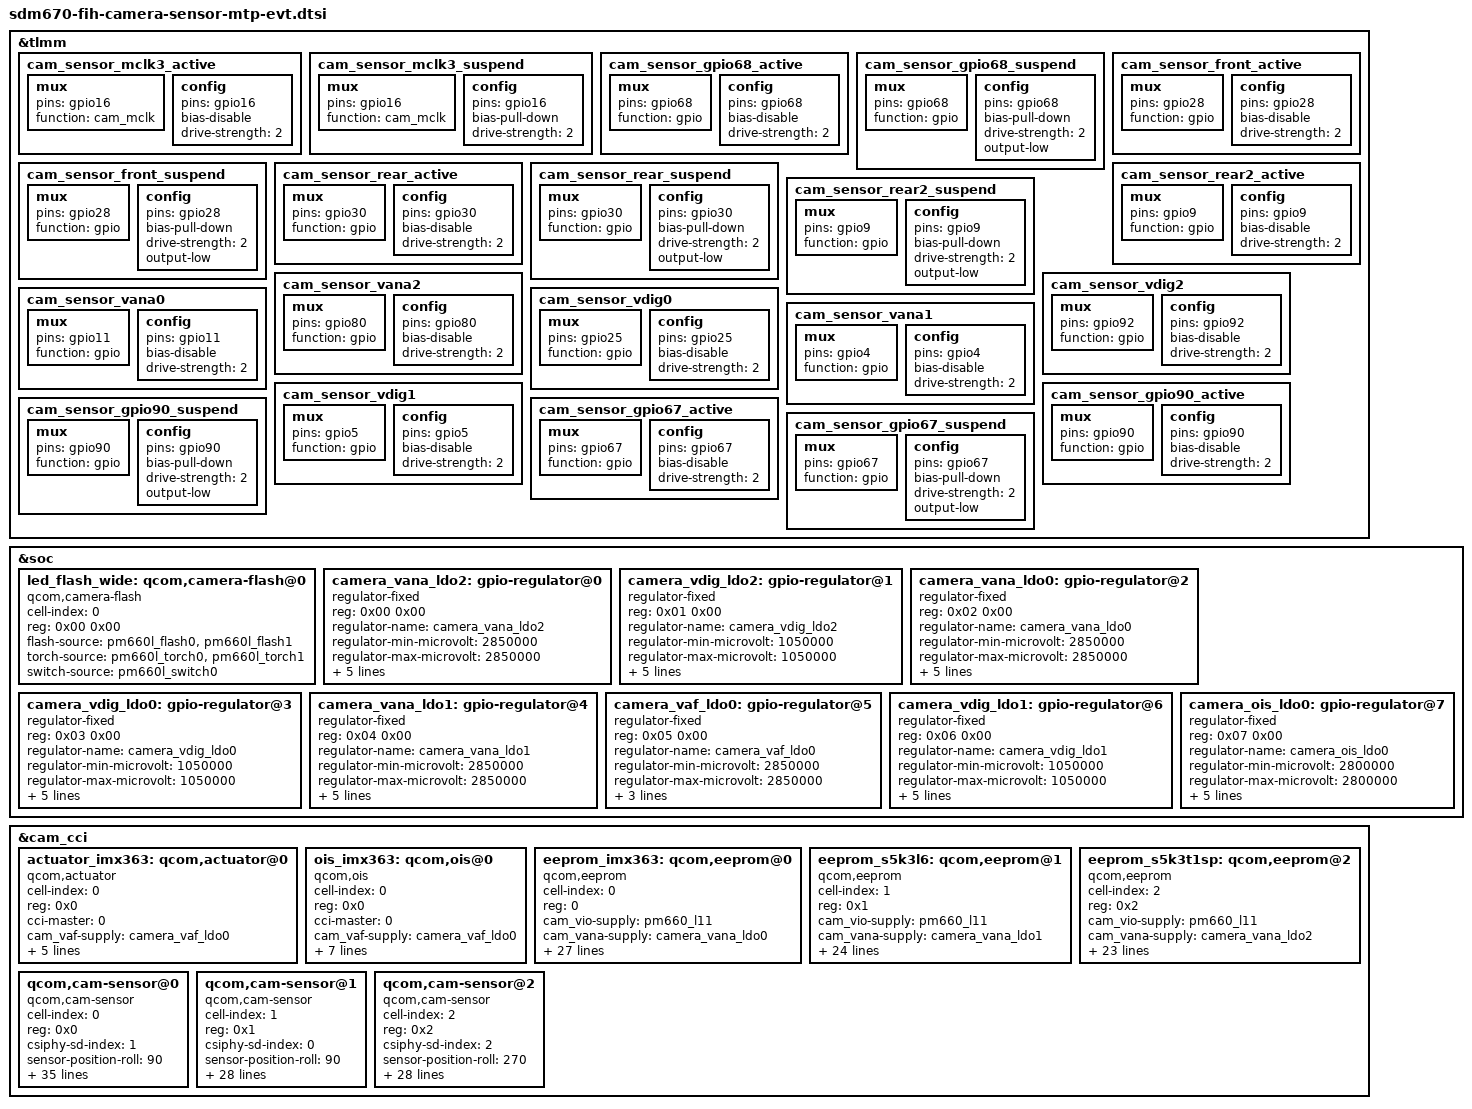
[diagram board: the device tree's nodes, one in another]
/*
 * Base on sdm670-camera-sensor-mtp.dtsi to overwrite setting
 */
 
&tlmm {
	/* Delete pinctrl node*/
	/delete-node/cam_sensor_front_active;
	/delete-node/cam_sensor_front_suspend;
	/delete-node/cam_sensor_rear_active;
	/delete-node/cam_sensor_rear_suspend;
	/delete-node/cam_sensor_rear2_active;
	/delete-node/cam_sensor_rear2_suspend;

	cam_sensor_mclk3_active: cam_sensor_mclk3_active {
		/* MCLK3 */
		mux {
			pins = "gpio16";
			function = "cam_mclk";
		};

		config {
			pins = "gpio16";
			bias-disable; /* No PULL */
			drive-strength = <2>; /* 2 MA */
		};
	};

	cam_sensor_mclk3_suspend: cam_sensor_mclk3_suspend {
		/* MCLK3 */
		mux {
			pins = "gpio16";
			function = "cam_mclk";
		};

		config {
			pins = "gpio16";
			bias-pull-down; /* PULL DOWN */
			drive-strength = <2>; /* 2 MA */
		};
	};

	cam_sensor_gpio68_active: cam_sensor_gpio68_active {
		/* RESET  */
		mux {
			pins = "gpio68";
			function = "gpio";
		};

		config {
			pins = "gpio68";
			bias-disable; /* No PULL */
			drive-strength = <2>; /* 2 MA */
		};
	};

	cam_sensor_gpio68_suspend: cam_sensor_gpio68_suspend {
		/* RESET */
		mux {
			pins = "gpio68";
			function = "gpio";
		};

		config {
			pins = "gpio68";
			bias-pull-down; /* PULL DOWN */
			drive-strength = <2>; /* 2 MA */
			output-low;
		};
	};

	cam_sensor_front_active: cam_sensor_front_active {
		/* RESET  */
		mux {
			pins = "gpio28";
			function = "gpio";
		};

		config {
			pins = "gpio28";
			bias-disable; /* No PULL */
			drive-strength = <2>; /* 2 MA */
		};
	};

	cam_sensor_front_suspend: cam_sensor_front_suspend {
		/* RESET */
		mux {
			pins = "gpio28";
			function = "gpio";
		};

		config {
			pins = "gpio28";
			bias-pull-down; /* PULL DOWN */
			drive-strength = <2>; /* 2 MA */
			output-low;
		};
	};

	cam_sensor_rear_active: cam_sensor_rear_active {
		/* RESET */
		mux {
			pins = "gpio30";
			function = "gpio";
		};

		config {
			pins = "gpio30";
			bias-disable; /* No PULL */
			drive-strength = <2>; /* 2 MA */
		};
	};

	cam_sensor_rear_suspend: cam_sensor_rear_suspend {
		/* RESET */
		mux {
			pins = "gpio30";
			function = "gpio";
		};

		config {
			pins = "gpio30";
			bias-pull-down; /* PULL DOWN */
			drive-strength = <2>; /* 2 MA */
			output-low;
		};
	};

	cam_sensor_rear2_active: cam_sensor_rear2_active {
		/* RESET */
		mux {
			pins = "gpio9";
			function = "gpio";
		};

		config {
			pins = "gpio9";
			bias-disable; /* No PULL */
			drive-strength = <2>; /* 2 MA */
		};
	};

	cam_sensor_rear2_suspend: cam_sensor_rear2_suspend {
		/* RESET */
		mux {
			pins = "gpio9";
			function = "gpio";
		};

		config {
			pins = "gpio9";
			bias-pull-down; /* PULL DOWN */
			drive-strength = <2>; /* 2 MA */
			output-low;
		};
	};
	
	cam_sensor_vana2: cam_sensor_vana2 {
		/*  FRONT AVDD LDO */
		mux {
			pins = "gpio80";
			function = "gpio";
		};

		config {
			pins = "gpio80";
			bias-disable; /* No PULL */
			drive-strength = <2>; /* 2 MA */
		};
	};

	cam_sensor_vdig2: cam_sensor_vdig2 {
		/*  FRONT VDIG LDO */
		mux {
			pins = "gpio92";
			function = "gpio";
		};

		config {
			pins = "gpio92";
			bias-disable; /* No PULL */
			drive-strength = <2>; /* 2 MA */
		};
	};

	cam_sensor_vana0: cam_sensor_vana0 {
		/*  WIDE AVDD LDO */
		mux {
			pins = "gpio11";
			function = "gpio";
		};

		config {
			pins = "gpio11";
			bias-disable; /* No PULL */
			drive-strength = <2>; /* 2 MA */
		};
	};

	cam_sensor_vdig0: cam_sensor_vdig0 {
		/*  WIDE VDIG LDO */
		mux {
			pins = "gpio25";
			function = "gpio";
		};

		config {
			pins = "gpio25";
			bias-disable; /* No PULL */
			drive-strength = <2>; /* 2 MA */
		};
	};

	cam_sensor_vana1: cam_sensor_vana1 {
		/*  TELE AVDD LDO */
		mux {
			pins = "gpio4";
			function = "gpio";
		};

		config {
			pins = "gpio4";
			bias-disable; /* No PULL */
			drive-strength = <2>; /* 2 MA */
		};
	};

	cam_sensor_vdig1: cam_sensor_vdig1 {
		/*  TELE VDIG LDO */
		mux {
			pins = "gpio5";
			function = "gpio";
		};

		config {
			pins = "gpio5";
			bias-disable; /* No PULL */
			drive-strength = <2>; /* 2 MA */
		};
	};

	cam_sensor_gpio90_active: cam_sensor_gpio90_active {
		/* VAF  */
		mux {
			pins = "gpio90";
			function = "gpio";
		};

		config {
			pins = "gpio90";
			bias-disable; /* No PULL */
			drive-strength = <2>; /* 2 MA */
		};
	};

	cam_sensor_gpio90_suspend: cam_sensor_gpio90_suspend {
		/* VAF */
		mux {
			pins = "gpio90";
			function = "gpio";
		};

		config {
			pins = "gpio90";
			bias-pull-down; /* PULL DOWN */
			drive-strength = <2>; /* 2 MA */
			output-low;
		};
	};

	cam_sensor_gpio67_active: cam_sensor_gpio67_active {
		/* OIS  */
		mux {
			pins = "gpio67";
			function = "gpio";
		};

		config {
			pins = "gpio67";
			bias-disable; /* No PULL */
			drive-strength = <2>; /* 2 MA */
		};
	};

	cam_sensor_gpio67_suspend: cam_sensor_gpio67_suspend {
		/* OIS */
		mux {
			pins = "gpio67";
			function = "gpio";
		};

		config {
			pins = "gpio67";
			bias-pull-down; /* PULL DOWN */
			drive-strength = <2>; /* 2 MA */
			output-low;
		};
	};
};

&soc {
	/* Delete pinctrl node*/
	/delete-node/camera-flash@0;
	led_flash_wide: qcom,camera-flash@0 {
		cell-index = <0>;
		reg = <0x00 0x00>;
		compatible = "qcom,camera-flash";
		flash-source = <&pm660l_flash0 &pm660l_flash1>;
		torch-source = <&pm660l_torch0 &pm660l_torch1>;
		switch-source = <&pm660l_switch0>;
		status = "ok";
	};

	camera_vana_ldo2: gpio-regulator@0 {
		compatible = "regulator-fixed";
		reg = <0x00 0x00>;
		regulator-name = "camera_vana_ldo2";
		regulator-min-microvolt = <2850000>;
		regulator-max-microvolt = <2850000>;
		regulator-enable-ramp-delay = <233>;
		enable-active-high;
		gpio = <&tlmm 80 0>;
		pinctrl-names = "default";
		pinctrl-0 = <&cam_sensor_vana2>;
		vin-supply = <&pm660l_bob>;
	};

	camera_vdig_ldo2: gpio-regulator@1 {
		compatible = "regulator-fixed";
		reg = <0x01 0x00>;
		regulator-name = "camera_vdig_ldo2";
		regulator-min-microvolt = <1050000>;
		regulator-max-microvolt = <1050000>;
		regulator-enable-ramp-delay = <135>;
		enable-active-high;
		gpio = <&tlmm 92 0>;
		pinctrl-names = "default";
		pinctrl-0 = <&cam_sensor_vdig2>;
		vin-supply = <&pm660_s4>;
	};

	camera_vana_ldo0: gpio-regulator@2 {
		compatible = "regulator-fixed";
		reg = <0x02 0x00>;
		regulator-name = "camera_vana_ldo0";
		regulator-min-microvolt = <2850000>;
		regulator-max-microvolt = <2850000>;
		regulator-enable-ramp-delay = <233>;
		enable-active-high;
		gpio = <&tlmm 11 0>;
		pinctrl-names = "default";
		pinctrl-0 = <&cam_sensor_vana0>;
		vin-supply = <&pm660l_bob>;
	};

	camera_vdig_ldo0: gpio-regulator@3 {
		compatible = "regulator-fixed";
		reg = <0x03 0x00>;
		regulator-name = "camera_vdig_ldo0";
		regulator-min-microvolt = <1050000>;
		regulator-max-microvolt = <1050000>;
		regulator-enable-ramp-delay = <135>;
		enable-active-high;
		gpio = <&tlmm 25 0>;
		pinctrl-names = "default";
		pinctrl-0 = <&cam_sensor_vdig0>;
		vin-supply = <&pm660_s4>;
	};

	camera_vana_ldo1: gpio-regulator@4 {
		compatible = "regulator-fixed";
		reg = <0x04 0x00>;
		regulator-name = "camera_vana_ldo1";
		regulator-min-microvolt = <2850000>;
		regulator-max-microvolt = <2850000>;
		regulator-enable-ramp-delay = <233>;
		enable-active-high;
		gpio = <&tlmm 4 0>;
		pinctrl-names = "default";
		pinctrl-0 = <&cam_sensor_vana1>;
		vin-supply = <&pm660l_bob>;
	};

	camera_vaf_ldo0: gpio-regulator@5 {
		compatible = "regulator-fixed";
		reg = <0x05 0x00>;
		regulator-name = "camera_vaf_ldo0";
		regulator-min-microvolt = <2850000>;
		regulator-max-microvolt = <2850000>;
		regulator-enable-ramp-delay = <100>;
		enable-active-high;
		gpio = <&tlmm 90 0>;
	};

	camera_vdig_ldo1: gpio-regulator@6 {
		compatible = "regulator-fixed";
		reg = <0x06 0x00>;
		regulator-name = "camera_vdig_ldo1";
		regulator-min-microvolt = <1050000>;
		regulator-max-microvolt = <1050000>;
		regulator-enable-ramp-delay = <135>;
		enable-active-high;
		gpio = <&tlmm 5 0>;
		pinctrl-names = "default";
		pinctrl-0 = <&cam_sensor_vdig1>;
		vin-supply = <&pm660_s4>;
	};

	camera_ois_ldo0: gpio-regulator@7 {
		compatible = "regulator-fixed";
		reg = <0x07 0x00>;
		regulator-name = "camera_ois_ldo0";
		regulator-min-microvolt = <2800000>;
		regulator-max-microvolt = <2800000>;
		regulator-enable-ramp-delay = <100>;
		enable-active-high;
		gpio = <&tlmm 67 0>;
		pinctrl-names = "default";
		pinctrl-0 = <&cam_sensor_gpio67_active>;
		vin-supply = <&pm660l_bob>;
	};
};

/* Delete cam_cci node*/
&cam_cci{
        /delete-node/qcom,cam-sensor@0;
        /delete-node/qcom,cam-sensor@1;
        /delete-node/qcom,cam-sensor@2;
        /delete-node/qcom,eeprom@0;
        /delete-node/qcom,eeprom@1;
        /delete-node/qcom,eeprom@2;
        /delete-node/qcom,actuator@0;
        /delete-node/qcom,ois@0;
};

&cam_cci {
	actuator_imx363: qcom,actuator@0 {
		cell-index = <0>;
		reg = <0x0>;
		compatible = "qcom,actuator";
		cci-master = <0>;
		cam_vaf-supply = <&camera_vaf_ldo0>;
		regulator-names = "cam_vaf";
		rgltr-cntrl-support;
		rgltr-min-voltage = <2850000>;
		rgltr-max-voltage = <2850000>;
		rgltr-load-current = <0>;
	};

	ois_imx363: qcom,ois@0 {
		cell-index = <0>;
		reg = <0x0>;
		compatible = "qcom,ois";
		cci-master = <0>;
		cam_vaf-supply = <&camera_vaf_ldo0>;
		cam_vio-supply = <&pm660_l11>;
		cam_vana-supply = <&camera_ois_ldo0>;
		regulator-names = "cam_vaf", "cam_vio", "cam_vana";
		rgltr-cntrl-support;
		rgltr-min-voltage = <2850000 1800000 2800000>;
		rgltr-max-voltage = <2850000 1800000 2800000>;
		rgltr-load-current = <0 0 0>;
		status = "ok";
	};

	eeprom_imx363: qcom,eeprom@0 {
		cell-index = <0>;
		reg = <0>;
		compatible = "qcom,eeprom";
		cam_vio-supply = <&pm660_l11>;
		cam_vana-supply = <&camera_vana_ldo0>;
		cam_vdig-supply = <&camera_vdig_ldo0>;
		cam_clk-supply = <&titan_top_gdsc>;
		regulator-names = "cam_vio", "cam_vana", "cam_vdig",
			"cam_clk";
		rgltr-cntrl-support;
		rgltr-min-voltage = <1800000 2850000 1050000 0>;
		rgltr-max-voltage = <1800000 2850000 1050000 0>;
		rgltr-load-current = <0 80000 105000 0>;
		gpio-no-mux = <0>;
		pinctrl-names = "cam_default", "cam_suspend";
		pinctrl-0 = <&cam_sensor_mclk3_active
				&cam_sensor_rear_active
				&cam_sensor_gpio68_active>;
		pinctrl-1 = <&cam_sensor_mclk3_suspend
				&cam_sensor_rear_suspend
				&cam_sensor_gpio68_suspend>;
		gpios = <&tlmm 16 0>,
			<&tlmm 30 0>,
			<&tlmm 68 0>;
		gpio-reset = <1>;
		gpio-custom1 = <2>;
		gpio-req-tbl-num = <0 1 2>;
		gpio-req-tbl-flags = <1 0 0>;
		gpio-req-tbl-label = "CAMIF_MCLK3",
					"CAM_RESET0",
					"CAM_CUSTOM0";
		sensor-mode = <0>;
		cci-master = <0>;
		status = "ok";
		clocks = <&clock_camcc CAM_CC_MCLK3_CLK>;
		clock-names = "cam_clk";
		clock-cntl-level = "turbo";
		clock-rates = <24000000>;
	};

	eeprom_s5k3l6: qcom,eeprom@1 {
		cell-index = <1>;
		reg = <0x1>;
		compatible = "qcom,eeprom";
		cam_vio-supply = <&pm660_l11>;
		cam_vana-supply = <&camera_vana_ldo1>;
		cam_vdig-supply = <&camera_vdig_ldo1>;
		cam_clk-supply = <&titan_top_gdsc>;
		regulator-names = "cam_vdig", "cam_vio", "cam_vana",
			"cam_clk";
		rgltr-cntrl-support;
		rgltr-min-voltage = <1050000 1800000 2850000 0>;
		rgltr-max-voltage = <1050000 1800000 2850000 0>;
		rgltr-load-current = <105000 0 80000 0>;
		gpio-no-mux = <0>;
		pinctrl-names = "cam_default", "cam_suspend";
		pinctrl-0 = <&cam_sensor_mclk0_active
				&cam_sensor_rear2_active>;
		pinctrl-1 = <&cam_sensor_mclk0_suspend
				&cam_sensor_rear2_suspend>;
		gpios = <&tlmm 13 0>,
			<&tlmm 9 0>;
		gpio-reset = <1>;
		gpio-req-tbl-num = <0 1>;
		gpio-req-tbl-flags = <1 0>;
		gpio-req-tbl-label = "CAMIF_MCLK0",
					"CAM_RESET2";
		sensor-position = <0>;
		sensor-mode = <0>;
		cci-master = <1>;
		status = "ok";
		clocks = <&clock_camcc CAM_CC_MCLK0_CLK>;
		clock-names = "cam_clk";
		clock-cntl-level = "turbo";
		clock-rates = <24000000>;
	};

	eeprom_s5k3t1sp: qcom,eeprom@2 {
		cell-index = <2>;
		reg = <0x2>;
		compatible = "qcom,eeprom";
		cam_vio-supply = <&pm660_l11>;
		cam_vana-supply = <&camera_vana_ldo2>;
		cam_vdig-supply = <&camera_vdig_ldo2>;
		cam_clk-supply = <&titan_top_gdsc>;
		regulator-names = "cam_vdig", "cam_vio", "cam_vana",
			"cam_clk";
		rgltr-cntrl-support;
		rgltr-min-voltage = <1050000 1800000 2850000 0>;
		rgltr-max-voltage = <1050000 1800000 2850000 0>;
		rgltr-load-current = <105000 0 80000 0>;
		gpio-no-mux = <0>;
		pinctrl-names = "cam_default", "cam_suspend";
		pinctrl-0 = <&cam_sensor_mclk2_active
				&cam_sensor_front_active>;
		pinctrl-1 = <&cam_sensor_mclk2_suspend
				&cam_sensor_front_suspend>;
		gpios = <&tlmm 15 0>,
			<&tlmm 28 0>;
		gpio-reset = <1>;
		gpio-req-tbl-num = <0 1>;
		gpio-req-tbl-flags = <1 0>;
		gpio-req-tbl-label = "CAMIF_MCLK2",
					"CAM_RESET1";
		sensor-mode = <0>;
		cci-master = <1>;
		status = "ok";
		clocks = <&clock_camcc CAM_CC_MCLK2_CLK>;
		clock-names = "cam_clk";
		clock-cntl-level = "turbo";
		clock-rates = <24000000>;
	};

       /* Wide Camera*/
	qcom,cam-sensor@0 {
		cell-index = <0>;
		compatible = "qcom,cam-sensor";
		reg = <0x0>;
		csiphy-sd-index = <1>;
		sensor-position-roll = <90>;
		sensor-position-pitch = <0>;
		sensor-position-yaw = <180>;
		led-flash-src = <&led_flash_wide>;
		actuator-src = <&actuator_imx363>;
		eeprom-src = <&eeprom_imx363>;
		ois-src = <&ois_imx363>;
		cam_vio-supply = <&pm660_l11>;
		cam_vana-supply = <&camera_vana_ldo0>;
		cam_vdig-supply = <&camera_vdig_ldo0>;
		cam_clk-supply = <&titan_top_gdsc>;
		regulator-names = "cam_vio", "cam_vana", "cam_vdig",
			"cam_clk";
		rgltr-cntrl-support;
		rgltr-min-voltage = <1800000 2850000 1050000 0>;
		rgltr-max-voltage = <1800000 2850000 1050000 0>;
		rgltr-load-current = <0 80000 105000 0>;
		gpio-no-mux = <0>;
		pinctrl-names = "cam_default", "cam_suspend";
		pinctrl-0 = <&cam_sensor_mclk3_active
				&cam_sensor_rear_active
				&cam_sensor_gpio68_active>;
		pinctrl-1 = <&cam_sensor_mclk3_suspend
				&cam_sensor_rear_suspend
				&cam_sensor_gpio68_suspend>;
		gpios = <&tlmm 16 0>,
			<&tlmm 30 0>,
			<&tlmm 68 0>;
		gpio-reset = <1>;
		gpio-custom1 = <2>;
		gpio-req-tbl-num = <0 1 2>;
		gpio-req-tbl-flags = <1 0 0>;
		gpio-req-tbl-label = "CAMIF_MCLK3",
					"CAM_RESET0",
					"CAM_CUSTOM0";
		sensor-mode = <0>;
		cci-master = <0>;
		status = "ok";
		clocks = <&clock_camcc CAM_CC_MCLK3_CLK>;
		clock-names = "cam_clk";
		clock-cntl-level = "turbo";
		clock-rates = <24000000>;
	};

	/* Tele Camera*/
	qcom,cam-sensor@1 {
		cell-index = <1>;
		compatible = "qcom,cam-sensor";
		reg = <0x1>;
		csiphy-sd-index = <0>;
		sensor-position-roll = <90>;
		sensor-position-pitch = <0>;
		sensor-position-yaw = <180>;
		eeprom-src = <&eeprom_s5k3l6>;
		cam_vio-supply = <&pm660_l11>;
		cam_vana-supply = <&camera_vana_ldo1>;
		cam_vdig-supply = <&camera_vdig_ldo1>;
		cam_clk-supply = <&titan_top_gdsc>;
		regulator-names = "cam_vdig", "cam_vio", "cam_vana",
			"cam_clk";
		rgltr-cntrl-support;
		rgltr-min-voltage = <1050000 1800000 2850000 0>;
		rgltr-max-voltage = <1050000 1800000 2850000 0>;
		rgltr-load-current = <105000 0 80000 0>;
		gpio-no-mux = <0>;
		pinctrl-names = "cam_default", "cam_suspend";
		pinctrl-0 = <&cam_sensor_mclk0_active
				&cam_sensor_rear2_active>;
		pinctrl-1 = <&cam_sensor_mclk0_suspend
				&cam_sensor_rear2_suspend>;
		gpios = <&tlmm 13 0>,
			<&tlmm 9 0>;
		gpio-reset = <1>;
		gpio-req-tbl-num = <0 1>;
		gpio-req-tbl-flags = <1 0>;
		gpio-req-tbl-label = "CAMIF_MCLK0",
					"CAM_RESET2";
		sensor-mode = <0>;
		cci-master = <1>;
		status = "ok";
		clocks = <&clock_camcc CAM_CC_MCLK0_CLK>;
		clock-names = "cam_clk";
		clock-cntl-level = "turbo";
		clock-rates = <24000000>;
	};

	/* Front Camera*/
	qcom,cam-sensor@2 {
		cell-index = <2>;
		compatible = "qcom,cam-sensor";
		reg = <0x2>;
		csiphy-sd-index = <2>;
		sensor-position-roll = <270>;
		sensor-position-pitch = <0>;
		sensor-position-yaw = <0>;
		eeprom-src = <&eeprom_s5k3t1sp>;
		cam_vio-supply = <&pm660_l11>;
		cam_vana-supply = <&camera_vana_ldo2>;
		cam_vdig-supply = <&camera_vdig_ldo2>;
		cam_clk-supply = <&titan_top_gdsc>;
		regulator-names = "cam_vdig", "cam_vio", "cam_vana",
			"cam_clk";
		rgltr-cntrl-support;
		rgltr-min-voltage = <1050000 1800000 2850000 0>;
		rgltr-max-voltage = <1050000 1800000 2850000 0>;
		rgltr-load-current = <105000 0 80000 0>;
		gpio-no-mux = <0>;
		pinctrl-names = "cam_default", "cam_suspend";
		pinctrl-0 = <&cam_sensor_mclk2_active
				&cam_sensor_front_active>;
		pinctrl-1 = <&cam_sensor_mclk2_suspend
				&cam_sensor_front_suspend>;
		gpios = <&tlmm 15 0>,
			<&tlmm 28 0>;
		gpio-reset = <1>;
		gpio-req-tbl-num = <0 1>;
		gpio-req-tbl-flags = <1 0>;
		gpio-req-tbl-label = "CAMIF_MCLK2",
					"CAM_RESET1";
		sensor-mode = <0>;
		cci-master = <1>;
		status = "ok";
		clocks = <&clock_camcc CAM_CC_MCLK2_CLK>;
		clock-names = "cam_clk";
		clock-cntl-level = "turbo";
		clock-rates = <24000000>;
	};
};
